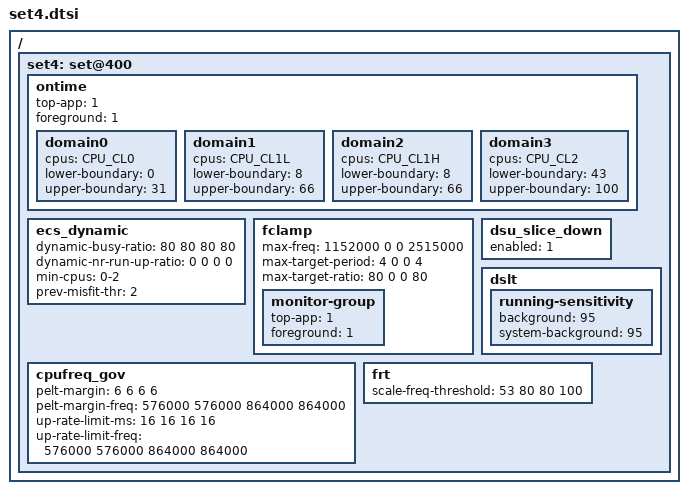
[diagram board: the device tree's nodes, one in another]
/ {
	/* balance mode - default */
	set4: set@400 {
		/* Ontime Migration */
		ontime {
			top-app		= <1>;
			foreground	= <1>;

			domain0 {
				cpus = CPU_CL0;
				lower-boundary = <0>;
				upper-boundary = <31>;
			};
			domain1 {
				cpus = CPU_CL1L;
				lower-boundary = <8>;
				upper-boundary = <66>;
			};
			domain2 {
				cpus = CPU_CL1H;
				lower-boundary = <8>;
				upper-boundary = <66>;
			};
			domain3 {
				cpus = CPU_CL2;
				lower-boundary = <43>;
				upper-boundary = <100>;
			};
		};

		ecs_dynamic {
			dynamic-busy-ratio		= <80 80 80 80>;
			dynamic-nr-run-up-ratio		= <0 0 0 0>;		/* for B7 */
			min-cpus = "0-2";
			prev-misfit-thr = < 2 >;		/* for B7 */
		};

		fclamp {
			max-freq          = < 1152000       0      0 2515000>;
			max-target-period = <       4       0      0       4>;
			max-target-ratio  = <      80       0      0      80>;

			monitor-group {
				top-app         = <1>;
				foreground      = <1>;
			};
		};

		cpufreq_gov {
				/* LIT MED-L MED-H BIG */
			pelt-margin = < 6 6 6 6 >;
			pelt-margin-freq = <576000 576000 864000 864000 >;		/* for B7 */
			up-rate-limit-ms = < 16 16 16 16 >;
			up-rate-limit-freq = <576000 576000 864000 864000 >;		/* for B7 */
		};

		dsu_slice_down {
			enabled = <1>;
		};

		dslt {
			running-sensitivity {
				background = <95>;
				system-background = <95>;
			};
		};

		frt {
			scale-freq-threshold = < 53 80 80 100 >;
		};
	};
};
